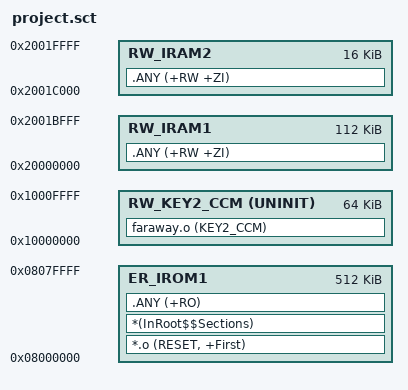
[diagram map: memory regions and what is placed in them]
LR_IROM1 0x08000000 0x00080000 {
  ER_IROM1 0x08000000 0x00080000 {
    *.o (RESET, +First)
    *(InRoot$$Sections)
    .ANY (+RO)
  }
  RW_KEY2_CCM 0x10000000 UNINIT 0x00010000 {
    faraway.o (KEY2_CCM)
  }
  RW_IRAM1 0x20000000 0x0001C000 {
    .ANY (+RW +ZI)
  }
  RW_IRAM2 0x2001C000 0x00004000 {
    .ANY (+RW +ZI)
  }
}
